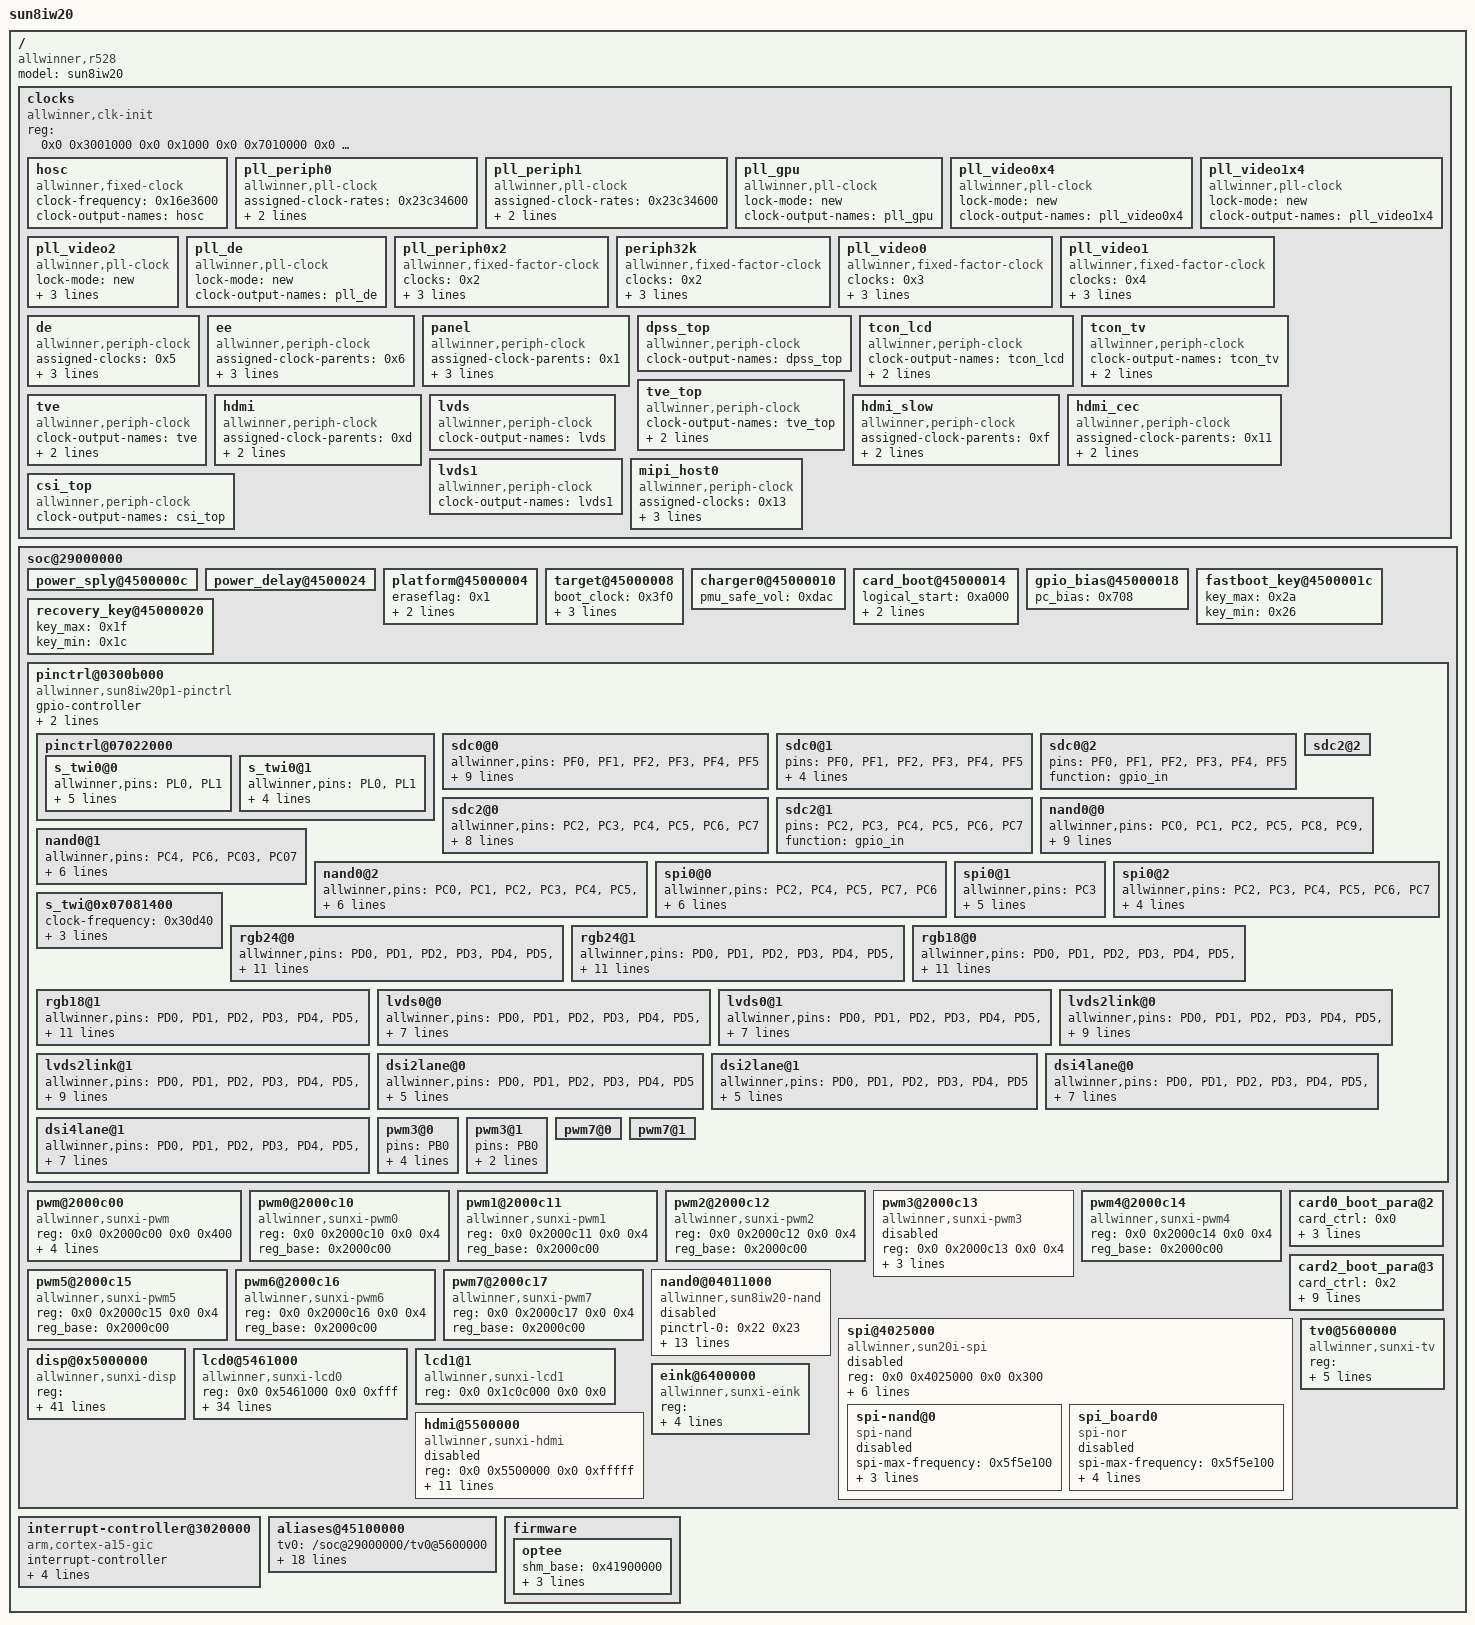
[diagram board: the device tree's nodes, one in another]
/dts-v1/;

/ {
	model = "sun8iw20";
	compatible = "allwinner,r528", "arm,sun8iw20p1";
	#address-cells = <0x2>;
	#size-cells = <0x2>;

	clocks {
		compatible = "allwinner,clk-init";
		device_type = "clocks";
		#address-cells = <0x2>;
		#size-cells = <0x2>;
		ranges;
		reg = <0x0 0x3001000 0x0 0x1000 0x0 0x7010000 0x0 0x400 0x0 0x7000000 0x0 0x4>;

		hosc {
			#clock-cells = <0x0>;
			compatible = "allwinner,fixed-clock";
			clock-frequency = <0x16e3600>;
			clock-output-names = "hosc";
			phandle = <0xf>;
		};

		pll_periph0 {
			#clock-cells = <0x0>;
			compatible = "allwinner,pll-clock";
			assigned-clock-rates = <0x23c34600>;
			lock-mode = "new";
			clock-output-names = "pll_periph0";
			phandle = <0x2>;
		};

		pll_periph1 {
			#clock-cells = <0x0>;
			compatible = "allwinner,pll-clock";
			assigned-clock-rates = <0x23c34600>;
			lock-mode = "new";
			clock-output-names = "pll_periph1";
		};

		pll_gpu {
			#clock-cells = <0x0>;
			compatible = "allwinner,pll-clock";
			lock-mode = "new";
			clock-output-names = "pll_gpu";
		};

		pll_video0x4 {
			#clock-cells = <0x0>;
			compatible = "allwinner,pll-clock";
			lock-mode = "new";
			clock-output-names = "pll_video0x4";
			phandle = <0x3>;
		};

		pll_video1x4 {
			#clock-cells = <0x0>;
			compatible = "allwinner,pll-clock";
			lock-mode = "new";
			clock-output-names = "pll_video1x4";
			phandle = <0x4>;
		};

		pll_video2 {
			#clock-cells = <0x0>;
			compatible = "allwinner,pll-clock";
			lock-mode = "new";
			assigned-clocks = <0x1>;
			assigned-clock-rates = <0x1406f400>;
			clock-output-names = "pll_video2";
			phandle = <0x1>;
		};

		pll_de {
			#clock-cells = <0x0>;
			compatible = "allwinner,pll-clock";
			lock-mode = "new";
			clock-output-names = "pll_de";
		};

		pll_periph0x2 {
			#clock-cells = <0x0>;
			compatible = "allwinner,fixed-factor-clock";
			clocks = <0x2>;
			clock-mult = <0x2>;
			clock-div = <0x1>;
			clock-output-names = "pll_periph0x2";
			phandle = <0x6>;
		};

		periph32k {
			#clock-cells = <0x0>;
			compatible = "allwinner,fixed-factor-clock";
			clocks = <0x2>;
			clock-mult = <0x2>;
			clock-div = <0x8f0d>;
			clock-output-names = "periph32k";
			phandle = <0x11>;
		};

		pll_video0 {
			#clock-cells = <0x0>;
			compatible = "allwinner,fixed-factor-clock";
			clocks = <0x3>;
			clock-mult = <0x1>;
			clock-div = <0x4>;
			clock-output-names = "pll_video0";
			phandle = <0xd>;
		};

		pll_video1 {
			#clock-cells = <0x0>;
			compatible = "allwinner,fixed-factor-clock";
			clocks = <0x4>;
			clock-mult = <0x1>;
			clock-div = <0x4>;
			clock-output-names = "pll_video1";
		};

		de {
			#clock-cells = <0x0>;
			compatible = "allwinner,periph-clock";
			assigned-clocks = <0x5>;
			assigned-clock-parents = <0x6>;
			assigned-clock-rates = <0x11e1a300>;
			clock-output-names = "de";
			phandle = <0x5>;
		};

		ee {
			#clock-cells = <0x0>;
			compatible = "allwinner,periph-clock";
			assigned-clock-parents = <0x6>;
			assigned-clock-rates = <0x11e1a300>;
			assigned-clocks = <0x7>;
			clock-output-names = "ee";
			phandle = <0x7>;
		};

		panel {
			#clock-cells = <0x0>;
			compatible = "allwinner,periph-clock";
			assigned-clock-parents = <0x1>;
			assigned-clock-rates = <0x1c9c380>;
			assigned-clocks = <0x8>;
			clock-output-names = "panel";
			phandle = <0x8>;
		};

		dpss_top {
			#clock-cells = <0x0>;
			compatible = "allwinner,periph-clock";
			clock-output-names = "dpss_top";
			phandle = <0x29>;
		};

		tcon_lcd {
			#clock-cells = <0x0>;
			compatible = "allwinner,periph-clock";
			clock-output-names = "tcon_lcd";
			assigned-clocks = <0x9>;
			assigned-clock-parents = <0x3>;
			phandle = <0x9>;
		};

		tcon_tv {
			#clock-cells = <0x0>;
			compatible = "allwinner,periph-clock";
			clock-output-names = "tcon_tv";
			assigned-clocks = <0xa>;
			assigned-clock-parents = <0x4>;
			phandle = <0xa>;
		};

		tve_top {
			#clock-cells = <0x0>;
			compatible = "allwinner,periph-clock";
			clock-output-names = "tve_top";
			assigned-clock-parents = <0x4>;
			assigned-clocks = <0xb>;
			phandle = <0xb>;
		};

		tve {
			#clock-cells = <0x0>;
			compatible = "allwinner,periph-clock";
			clock-output-names = "tve";
			assigned-clock-parents = <0x4>;
			assigned-clocks = <0xc>;
			phandle = <0xc>;
		};

		hdmi {
			#clock-cells = <0x0>;
			compatible = "allwinner,periph-clock";
			assigned-clock-parents = <0xd>;
			assigned-clocks = <0xe>;
			clock-output-names = "hdmi";
			phandle = <0xe>;
		};

		hdmi_slow {
			#clock-cells = <0x0>;
			compatible = "allwinner,periph-clock";
			assigned-clock-parents = <0xf>;
			assigned-clocks = <0x10>;
			clock-output-names = "hdmi_slow";
			phandle = <0x10>;
		};

		hdmi_cec {
			#clock-cells = <0x0>;
			compatible = "allwinner,periph-clock";
			assigned-clock-parents = <0x11>;
			assigned-clocks = <0x12>;
			clock-output-names = "hdmi_cec";
			phandle = <0x12>;
		};

		lvds {
			#clock-cells = <0x0>;
			compatible = "allwinner,periph-clock";
			clock-output-names = "lvds";
			phandle = <0x2a>;
		};

		lvds1 {
			#clock-cells = <0x0>;
			compatible = "allwinner,periph-clock";
			clock-output-names = "lvds1";
		};

		mipi_host0 {
			#clock-cells = <0x0>;
			compatible = "allwinner,periph-clock";
			assigned-clocks = <0x13>;
			assigned-clock-parents = <0x2>;
			assigned-clock-rates = <0x8f0d180>;
			clock-output-names = "mipi_host0";
			phandle = <0x13>;
		};

		csi_top {
			#clock-cells = <0x0>;
			compatible = "allwinner,periph-clock";
			clock-output-names = "csi_top";
		};
	};

	soc@29000000 {
		#address-cells = <0x2>;
		#size-cells = <0x2>;

		power_sply@4500000c {
			device_type = "power_sply";
		};

		power_delay@4500024 {
			device_type = "power_delay";
		};

		platform@45000004 {
			device_type = "platform";
			eraseflag = <0x1>;
			next_work = <0x3>;
			debug_mode = <0x1>;
		};

		target@45000008 {
			device_type = "target";
			boot_clock = <0x3f0>;
			storage_type = <0xffffffff>;
			burn_key = <0x1>;
			dragonboard_test = <0x0>;
		};

		charger0@45000010 {
			device_type = "charger0";
			pmu_safe_vol = <0xdac>;
		};

		card_boot@45000014 {
			device_type = "card_boot";
			logical_start = <0xa000>;
			sprite_gpio0 = <0x14 0x7 0x6 0x1 0xffffffff 0xffffffff 0x1>;
		};

		gpio_bias@45000018 {
			device_type = "gpio_bias";
			pc_bias = <0x708>;
		};

		fastboot_key@4500001c {
			device_type = "fastboot_key";
			key_max = <0x2a>;
			key_min = <0x26>;
		};

		recovery_key@45000020 {
			device_type = "recovery_key";
			key_max = <0x1f>;
			key_min = <0x1c>;
		};

		pinctrl@0300b000 {
			compatible = "allwinner,sun8iw20p1-pinctrl";
			device_type = "pio";
			gpio-controller;
			#size-cells = <0x0>;
			#gpio-cells = <0x6>;
			input-debounce = <0x0 0x0 0x0 0x0 0x0 0x0 0x0 0x0 0x0>;
			phandle = <0x14>;

			pinctrl@07022000 {

				s_twi0@0 {
					allwinner,pins = "PL0", "PL1";
					allwinner,pname = "s_twi0_scl", "s_twi0_sda";
					allwinner,function = "s_twi0";
					allwinner,muxsel = <0x2>;
					allwinner,drive = <0x1>;
					allwinner,pull = <0x1>;
					phandle = <0x15>;
				};

				s_twi0@1 {
					allwinner,pins = "PL0", "PL1";
					allwinner,function = "io_disabled";
					allwinner,muxsel = <0x7>;
					allwinner,drive = <0x1>;
					allwinner,pull = <0x0>;
				};
			};

			sdc0@0 {
				allwinner,pins = "PF0", "PF1", "PF2", "PF3", "PF4", "PF5";
				allwinner,function = "sdc0";
				allwinner,muxsel = <0x2>;
				allwinner,drive = <0x3>;
				allwinner,pull = <0x1>;
				pins = "PF0", "PF1", "PF2", "PF3", "PF4", "PF5";
				function = "sdc0";
				drive-strength = <0x1e>;
				bias-pull-up;
				power-source = <0xce4>;
				phandle = <0x20>;
			};

			sdc0@1 {
				pins = "PF0", "PF1", "PF2", "PF3", "PF4", "PF5";
				function = "sdc0";
				drive-strength = <0x1e>;
				bias-pull-up;
				power-source = <0x708>;
			};

			sdc0@2 {
				pins = "PF0", "PF1", "PF2", "PF3", "PF4", "PF5";
				function = "gpio_in";
			};

			sdc2@0 {
				allwinner,pins = "PC2", "PC3", "PC4", "PC5", "PC6", "PC7";
				allwinner,function = "sdc2";
				allwinner,muxsel = <0x3>;
				allwinner,drive = <0x3>;
				allwinner,pull = <0x1>;
				pins = "PC2", "PC3", "PC4", "PC5", "PC6", "PC7";
				function = "sdc2";
				drive-strength = <0x1e>;
				bias-pull-up;
				phandle = <0x21>;
			};

			sdc2@1 {
				pins = "PC2", "PC3", "PC4", "PC5", "PC6", "PC7";
				function = "gpio_in";
			};

			sdc2@2 {
			};

			nand0@0 {
				allwinner,pins = "PC0", "PC1", "PC2", "PC5", "PC8", "PC9", "PC10", "PC11", "PC12", "PC13", "PC14", "PC15", "PC16";
				allwinner,pname = "nand0_we", "nand0_ale", "nand0_cle", "nand0_nre", "nand0_d0", "nand0_d1", "nand0_d2", "nand0_d3", "nand0_d4", "nand0_d5", "nand0_d6", "nand0_d7", "nand0_ndqs";
				allwinner,function = "nand0";
				allwinner,muxsel = <0x2>;
				allwinner,drive = <0x1>;
				allwinner,pull = <0x0>;
				phandle = <0x22>;
			};

			nand0@1 {
				allwinner,pins = "PC4", "PC6", "PC03", "PC07";
				allwinner,pname = "nand0_ce0", "nand0_rb0", "nand0_ce1", "nand0_rb1";
				allwinner,function = "nand0";
				allwinner,muxsel = <0x2>;
				allwinner,drive = <0x1>;
				allwinner,pull = <0x1>;
				phandle = <0x23>;
			};

			nand0@2 {
				allwinner,pins = "PC0", "PC1", "PC2", "PC3", "PC4", "PC5", "PC6", "PC7", "PC8", "PC9", "PC10", "PC11", "PC12", "PC13", "PC14", "PC15", "PC16";
				allwinner,function = "io_disabled";
				allwinner,muxsel = <0x7>;
				allwinner,drive = <0x1>;
				allwinner,pull = <0x0>;
				phandle = <0x24>;
			};

			spi0@0 {
				allwinner,pins = "PC2", "PC4", "PC5", "PC7", "PC6";
				allwinner,pname = "spi0_sclk", "spi0_mosi", "spi0_miso", "spi0_hold", "spi0_wp";
				allwinner,function = "spi0";
				allwinner,muxsel = <0x2>;
				allwinner,drive = <0x1>;
				allwinner,pull = <0x0>;
				phandle = <0x25>;
			};

			spi0@1 {
				allwinner,pins = "PC3";
				allwinner,pname = "spi0_cs0";
				allwinner,function = "spi0";
				allwinner,muxsel = <0x2>;
				allwinner,drive = <0x1>;
				allwinner,pull = <0x1>;
				phandle = <0x26>;
			};

			spi0@2 {
				allwinner,pins = "PC2", "PC3", "PC4", "PC5", "PC6", "PC7";
				allwinner,function = "gpio_in";
				allwinner,muxsel = <0x0>;
				allwinner,drive = <0x1>;
				allwinner,pull = <0x0>;
				phandle = <0x27>;
			};

			s_twi@0x07081400 {
				clock-frequency = <0x30d40>;
				pinctrl-0 = <0x15>;
				no_suspend = <0x1>;
				twi_drv_used = <0x1>;
				status = "okay";
			};

			rgb24@0 {
				allwinner,pins = "PD0", "PD1", "PD2", "PD3", "PD4", "PD5", "PD6", "PD7", "PD8", "PD9", "PD10", "PD11", "PD12", "PD13", "PD14", "PD15", "PD16", "PD17", "PD18", "PD19", "PD20", "PD21", "PB2", "PB3", "PB4", "PB5", "PB6", "PB7";
				allwinner,pname = "PD0", "PD1", "PD2", "PD3", "PD4", "PD5", "PD6", "PD7", "PD8", "PD9", "PD10", "PD11", "PD12", "PD13", "PD14", "PD15", "PD16", "PD17", "PD18", "PD19", "PD20", "PD21", "PB2", "PB3", "PB4", "PB5", "PB6", "PB7";
				allwinner,function = "rgb18";
				allwinner,muxsel = <0x2>;
				allwinner,drive = <0x3>;
				allwinner,pull = <0x0>;
			};

			rgb24@1 {
				allwinner,pins = "PD0", "PD1", "PD2", "PD3", "PD4", "PD5", "PD6", "PD7", "PD8", "PD9", "PD10", "PD11", "PD12", "PD13", "PD14", "PD15", "PD16", "PD17", "PD18", "PD19", "PD20", "PD21", "PB2", "PB3", "PB4", "PB5", "PB6", "PB7";
				allwinner,pname = "PD0", "PD1", "PD2", "PD3", "PD4", "PD5", "PD6", "PD7", "PD8", "PD9", "PD10", "PD11", "PD12", "PD13", "PD14", "PD15", "PD16", "PD17", "PD18", "PD19", "PD20", "PD21", "PB2", "PB3", "PB4", "PB5", "PB6", "PB7";
				allwinner,function = "rgb18_suspend";
				allwinner,muxsel = <0xf>;
				allwinner,drive = <0x1>;
				allwinner,pull = <0x0>;
			};

			rgb18@0 {
				allwinner,pins = "PD0", "PD1", "PD2", "PD3", "PD4", "PD5", "PD6", "PD7", "PD8", "PD9", "PD10", "PD11", "PD12", "PD13", "PD14", "PD15", "PD16", "PD17", "PD18", "PD19", "PD20", "PD21";
				allwinner,pname = "PD0", "PD1", "PD2", "PD3", "PD4", "PD5", "PD6", "PD7", "PD8", "PD9", "PD10", "PD11", "PD12", "PD13", "PD14", "PD15", "PD16", "PD17", "PD18", "PD19", "PD20", "PD21";
				allwinner,function = "rgb18";
				allwinner,muxsel = <0x2>;
				allwinner,drive = <0x3>;
				allwinner,pull = <0x0>;
			};

			rgb18@1 {
				allwinner,pins = "PD0", "PD1", "PD2", "PD3", "PD4", "PD5", "PD6", "PD7", "PD8", "PD9", "PD10", "PD11", "PD12", "PD13", "PD14", "PD15", "PD16", "PD17", "PD18", "PD19", "PD20", "PD21";
				allwinner,pname = "PD0", "PD1", "PD2", "PD3", "PD4", "PD5", "PD6", "PD7", "PD8", "PD9", "PD10", "PD11", "PD12", "PD13", "PD14", "PD15", "PD16", "PD17", "PD18", "PD19", "PD20", "PD21";
				allwinner,function = "rgb18_suspend";
				allwinner,muxsel = <0x7>;
				allwinner,drive = <0x1>;
				allwinner,pull = <0x0>;
			};

			lvds0@0 {
				allwinner,pins = "PD0", "PD1", "PD2", "PD3", "PD4", "PD5", "PD6", "PD7", "PD8", "PD9";
				allwinner,pname = "PD0", "PD1", "PD2", "PD3", "PD4", "PD5", "PD6", "PD7", "PD8", "PD9";
				allwinner,function = "lvds0";
				allwinner,muxsel = <0x3>;
				allwinner,drive = <0x3>;
				allwinner,pull = <0x0>;
				phandle = <0x2b>;
			};

			lvds0@1 {
				allwinner,pins = "PD0", "PD1", "PD2", "PD3", "PD4", "PD5", "PD6", "PD7", "PD8", "PD9";
				allwinner,pname = "PD0", "PD1", "PD2", "PD3", "PD4", "PD5", "PD6", "PD7", "PD8", "PD9";
				allwinner,function = "io_disabled";
				allwinner,muxsel = <0x7>;
				allwinner,drive = <0x3>;
				allwinner,pull = <0x0>;
				phandle = <0x2c>;
			};

			lvds2link@0 {
				allwinner,pins = "PD0", "PD1", "PD2", "PD3", "PD4", "PD5", "PD6", "PD7", "PD8", "PD9", "PD10", "PD11", "PD12", "PD13", "PD14", "PD15", "PD16", "PD17", "PD18", "PD19";
				allwinner,pname = "PD0", "PD1", "PD2", "PD3", "PD4", "PD5", "PD6", "PD7", "PD8", "PD9", "PD10", "PD11", "PD12", "PD13", "PD14", "PD15", "PD16", "PD17", "PD18", "PD19";
				allwinner,function = "lvds0";
				allwinner,muxsel = <0x3>;
				allwinner,drive = <0x3>;
				allwinner,pull = <0x0>;
			};

			lvds2link@1 {
				allwinner,pins = "PD0", "PD1", "PD2", "PD3", "PD4", "PD5", "PD6", "PD7", "PD8", "PD9", "PD10", "PD11", "PD12", "PD13", "PD14", "PD15", "PD16", "PD17", "PD18", "PD19";
				allwinner,pname = "PD0", "PD1", "PD2", "PD3", "PD4", "PD5", "PD6", "PD7", "PD8", "PD9", "PD10", "PD11", "PD12", "PD13", "PD14", "PD15", "PD16", "PD17", "PD18", "PD19";
				allwinner,function = "lvds0_suspend";
				allwinner,muxsel = <0xf>;
				allwinner,drive = <0x3>;
				allwinner,pull = <0x0>;
			};

			dsi2lane@0 {
				allwinner,pins = "PD0", "PD1", "PD2", "PD3", "PD4", "PD5";
				allwinner,pname = "PD0", "PD1", "PD2", "PD3", "PD4", "PD5";
				allwinner,function = "dsi2lane";
				allwinner,muxsel = <0x4>;
				allwinner,drive = <0x3>;
				allwinner,pull = <0x0>;
			};

			dsi2lane@1 {
				allwinner,pins = "PD0", "PD1", "PD2", "PD3", "PD4", "PD5";
				allwinner,pname = "PD0", "PD1", "PD2", "PD3", "PD4", "PD5";
				allwinner,function = "dsi2lane_suspend";
				allwinner,muxsel = <0xf>;
				allwinner,drive = <0x1>;
				allwinner,pull = <0x0>;
			};

			dsi4lane@0 {
				allwinner,pins = "PD0", "PD1", "PD2", "PD3", "PD4", "PD5", "PD6", "PD7", "PD8", "PD9";
				allwinner,pname = "PD0", "PD1", "PD2", "PD3", "PD4", "PD5", "PD6", "PD7", "PD8", "PD9";
				allwinner,function = "dsi4lane";
				allwinner,muxsel = <0x4>;
				allwinner,drive = <0x3>;
				allwinner,pull = <0x0>;
			};

			dsi4lane@1 {
				allwinner,pins = "PD0", "PD1", "PD2", "PD3", "PD4", "PD5", "PD6", "PD7", "PD8", "PD9";
				allwinner,pname = "PD0", "PD1", "PD2", "PD3", "PD4", "PD5", "PD6", "PD7", "PD8", "PD9";
				allwinner,function = "dsi4lane_suspend";
				allwinner,muxsel = <0x7>;
				allwinner,drive = <0x1>;
				allwinner,pull = <0x0>;
			};

			pwm3@0 {
				pins = "PB0";
				function = "pwm3";
				muxsel = <0x2>;
				drive-strength = <0xa>;
				bias-pull-up;
				phandle = <0x1e>;
			};

			pwm3@1 {
				pins = "PB0";
				muxsel = <0x0>;
				function = "gpio_in";
				phandle = <0x1f>;
			};

			pwm7@0 {
			};

			pwm7@1 {
			};
		};

		pwm@2000c00 {
			#pwm-cells = <0x3>;
			compatible = "allwinner,sunxi-pwm";
			reg = <0x0 0x2000c00 0x0 0x400>;
			pwm-number = <0x8>;
			pwm-base = <0x0>;
			sunxi-pwms = <0x16 0x17 0x18 0x19 0x1a 0x1b 0x1c 0x1d>;
		};

		pwm0@2000c10 {
			compatible = "allwinner,sunxi-pwm0";
			pinctrl-names = "active", "sleep";
			reg = <0x0 0x2000c10 0x0 0x4>;
			reg_base = <0x2000c00>;
			phandle = <0x16>;
		};

		pwm1@2000c11 {
			compatible = "allwinner,sunxi-pwm1";
			pinctrl-names = "active", "sleep";
			reg = <0x0 0x2000c11 0x0 0x4>;
			reg_base = <0x2000c00>;
			phandle = <0x17>;
		};

		pwm2@2000c12 {
			compatible = "allwinner,sunxi-pwm2";
			pinctrl-names = "active", "sleep";
			reg = <0x0 0x2000c12 0x0 0x4>;
			reg_base = <0x2000c00>;
			phandle = <0x18>;
		};

		pwm3@2000c13 {
			compatible = "allwinner,sunxi-pwm3";
			pinctrl-names = "active", "sleep";
			reg = <0x0 0x2000c13 0x0 0x4>;
			reg_base = <0x2000c00>;
			pinctrl-0 = <0x1e>;
			pinctrl-1 = <0x1f>;
			status = "disabled";
			phandle = <0x19>;
		};

		pwm4@2000c14 {
			compatible = "allwinner,sunxi-pwm4";
			pinctrl-names = "active", "sleep";
			reg = <0x0 0x2000c14 0x0 0x4>;
			reg_base = <0x2000c00>;
			phandle = <0x1a>;
		};

		pwm5@2000c15 {
			compatible = "allwinner,sunxi-pwm5";
			pinctrl-names = "active", "sleep";
			reg = <0x0 0x2000c15 0x0 0x4>;
			reg_base = <0x2000c00>;
			phandle = <0x1b>;
		};

		pwm6@2000c16 {
			compatible = "allwinner,sunxi-pwm6";
			pinctrl-names = "active", "sleep";
			reg = <0x0 0x2000c16 0x0 0x4>;
			reg_base = <0x2000c00>;
			phandle = <0x1c>;
		};

		pwm7@2000c17 {
			compatible = "allwinner,sunxi-pwm7";
			pinctrl-names = "active", "sleep";
			reg = <0x0 0x2000c17 0x0 0x4>;
			reg_base = <0x2000c00>;
			phandle = <0x1d>;
		};

		card0_boot_para@2 {
			device_type = "card0_boot_para";
			card_ctrl = <0x0>;
			card_high_speed = <0x1>;
			card_line = <0x4>;
			pinctrl-0 = <0x20>;
		};

		card2_boot_para@3 {
			device_type = "card2_boot_para";
			card_ctrl = <0x2>;
			card_high_speed = <0x1>;
			card_line = <0x4>;
			pinctrl-0 = <0x21>;
			sdc_ex_dly_used = <0x2>;
			sdc_io_1v8 = <0x1>;
			sdc_tm4_win_th = <0x8>;
			sdc_tm4_hs200_max_freq = <0x96>;
			sdc_tm4_hs400_max_freq = <0x64>;
			sdc_type = "tm4";
		};

		nand0@04011000 {
			device_type = "nand0";
			compatible = "allwinner,sun8iw20-nand";
			pinctrl-names = "default", "sleep";
			pinctrl-0 = <0x22 0x23>;
			pinctrl-1 = <0x24>;
			nand0_regulator1 = "vcc-nand";
			nand0_regulator2 = "none";
			nand0_cache_level = <0x55aaaa55>;
			nand0_flush_cache_num = <0x55aaaa55>;
			nand0_capacity_level = <0x55aaaa55>;
			nand0_id_number_ctl = <0x55aaaa55>;
			nand0_print_level = <0x55aaaa55>;
			nand0_p0 = <0x55aaaa55>;
			nand0_p1 = <0x55aaaa55>;
			nand0_p2 = <0x55aaaa55>;
			nand0_p3 = <0x55aaaa55>;
			chip_code = "sun8iw20";
			status = "disabled";
		};

		spi@4025000 {
			#address-cells = <0x1>;
			#size-cells = <0x0>;
			compatible = "allwinner,sun20i-spi";
			device_type = "spi0";
			reg = <0x0 0x4025000 0x0 0x300>;
			clock-frequency = <0x5f5e100>;
			pinctrl-0 = <0x25 0x26>;
			pinctrl-1 = <0x27>;
			pinctrl-names = "default", "sleep";
			spi_slave_mode = <0x0>;
			spi0_cs_number = <0x1>;
			spi0_cs_bitmap = <0x1>;
			status = "disabled";

			spi-nand@0 {
				compatible = "spi-nand";
				spi-max-frequency = <0x5f5e100>;
				reg = <0x0>;
				spi-rx-bus-width = <0x1>;
				spi-tx-bus-width = <0x1>;
				status = "disabled";
			};

			spi_board0 {
				device_type = "spi_board0";
				compatible = "spi-nor";
				spi-max-frequency = <0x5f5e100>;
				m25p,fast-read = <0x1>;
				reg = <0x0>;
				spi-rx-bus-width = <0x4>;
				spi-tx-bus-width = <0x4>;
				status = "disabled";
			};
		};

		disp@0x5000000 {
			compatible = "allwinner,sunxi-disp";
			reg = <0x0 0x5000000 0x0 0x3fffff 0x0 0x5460000 0x0 0xfff 0x0 0x5461000 0x0 0xfff 0x0 0x5470000 0x0 0xfff 0x0 0x5450000 0x0 0x1fff>;
			interrupts = <0x0 0x5a 0x4 0x0 0x5b 0x4 0x0 0x5c 0x4>;
			interrupt-parent = <0x28>;
			clocks = <0x5 0x29 0x9 0xa 0x2a 0x13>;
			boot_disp = <0x0>;
			boot_disp1 = <0x0>;
			boot_disp2 = <0x0>;
			fb_base = <0x0>;
			status = "okay";
			disp_init_enable = <0x1>;
			disp_mode = <0x0>;
			screen0_output_type = <0x1>;
			screen0_output_mode = <0x4>;
			screen1_output_type = <0x1>;
			screen1_output_mode = <0x4>;
			screen1_output_format = <0x0>;
			screen1_output_bits = <0x0>;
			screen1_output_eotf = <0x4>;
			screen1_output_cs = <0x101>;
			screen1_output_dvi_hdmi = <0x2>;
			screen1_output_range = <0x2>;
			screen1_output_scan = <0x0>;
			screen1_output_aspect_ratio = <0x8>;
			dev0_output_type = <0x1>;
			dev0_output_mode = <0x4>;
			dev0_screen_id = <0x0>;
			dev0_do_hpd = <0x0>;
			dev1_output_type = <0x1>;
			dev1_output_mode = <0x4>;
			dev1_screen_id = <0x1>;
			dev1_do_hpd = <0x0>;
			def_output_dev = <0x0>;
			hdmi_mode_check = <0x1>;
			fb0_format = <0x0>;
			fb0_width = <0x400>;
			fb0_height = <0x258>;
			fb1_format = <0x0>;
			fb1_width = <0x400>;
			fb1_height = <0x258>;
			chn_cfg_mode = <0x1>;
			disp_para_zone = <0x1>;
		};

		tv0@5600000 {
			compatible = "allwinner,sunxi-tv";
			reg = <0x0 0x5600000 0x0 0x3fff 0x0 0x5604000 0x0 0x3fff>;
			clocks = <0xb 0xc>;
			device_type = "tv0";
			pinctrl-names = "active", "sleep";
			status = "okay";
			interface = <0x1>;
			dac_type0 = <0x0>;
			dac_src0 = <0x0>;
		};

		lcd0@5461000 {
			#address-cells = <0x2>;
			#size-cells = <0x2>;
			compatible = "allwinner,sunxi-lcd0";
			reg = <0x0 0x5461000 0x0 0xfff>;
			pinctrl-names = "active", "sleep";
			status = "okay";
			lcd_used = <0x1>;
			lcd_driver_name = "default_lcd";
			lcd_backlight = <0x64>;
			lcd_if = <0x3>;
			lcd_x = <0x400>;
			lcd_y = <0x258>;
			lcd_width = <0x9a>;
			lcd_height = <0x56>;
			lcd_dclk_freq = <0x31>;
			lcd_pwm_used = <0x1>;
			lcd_pwm_ch = <0x2>;
			lcd_pwm_freq = <0xc350>;
			lcd_pwm_pol = <0x1>;
			lcd_pwm_max_limit = <0xff>;
			lcd_hbp = <0xa0>;
			lcd_ht = <0x52c>;
			lcd_hspw = <0x74>;
			lcd_vbp = <0x18>;
			lcd_vt = <0x275>;
			lcd_vspw = <0x3>;
			lcd_lvds_if = <0x0>;
			lcd_lvds_colordepth = <0x0>;
			lcd_lvds_mode = <0x0>;
			lcd_frm = <0x0>;
			lcd_hv_clk_phase = <0x0>;
			lcd_hv_sync_polarity = <0x0>;
			lcd_gamma_en = <0x0>;
			lcd_bright_curve_en = <0x0>;
			lcd_cmap_en = <0x0>;
			deu_mode = <0x0>;
			lcdgamma4iep = <0x16>;
			smart_color = <0x5a>;
			pinctrl-0 = <0x2b>;
			pinctrl-1 = <0x2c>;
		};

		lcd1@1 {
			compatible = "allwinner,sunxi-lcd1";
			reg = <0x0 0x1c0c000 0x0 0x0>;
			pinctrl-names = "active", "sleep";
			status = "okay";
		};

		hdmi@5500000 {
			compatible = "allwinner,sunxi-hdmi";
			reg = <0x0 0x5500000 0x0 0xfffff>;
			interrupts = <0x0 0x5d 0x4>;
			interrupt-parent = <0x28>;
			clocks = <0x10 0x12 0xa>;
			status = "disabled";
			hdmi_used = <0x0>;
			hdmi_power_cnt = <0x0>;
			hdmi_hdcp_enable = <0x1>;
			hdmi_hdcp22_enable = <0x0>;
			hdmi_cec_support = <0x1>;
			hdmi_cec_super_standby = <0x0>;
			ddc_en_io_ctrl = <0x0>;
			power_io_ctrl = <0x0>;
		};

		eink@6400000 {
			compatible = "allwinner,sunxi-eink";
			pinctrl-names = "active", "sleep";
			reg = <0x0 0x6400000 0x0 0x1ffff 0x0 0x6000000 0x0 0x3fffff>;
			interrupts = <0x0 0x5a 0x4 0x0 0x58 0x4>;
			clocks = <0x5 0x7 0x8>;
			interrupt-parent = <0x28>;
			status = "okay";
		};
	};

	interrupt-controller@3020000 {
		compatible = "arm,cortex-a15-gic", "arm,cortex-a9-gic";
		#interrupt-cells = <0x3>;
		#address-cells = <0x0>;
		device_type = "gic";
		interrupt-controller;
		reg = <0x0 0x3021000 0x0 0x1000 0x0 0x3022000 0x0 0x2000 0x0 0x3024000 0x0 0x2000 0x0 0x3026000 0x0 0x2000>;
		interrupts = <0x1 0x9 0xf04>;
		interrupt-parent = <0x28>;
		phandle = <0x28>;
	};

	aliases@45100000 {
		tv0 = "/soc@29000000/tv0@5600000";
		nand0 = "/soc@29000000/nand0@04011000";
		twi6 = "/soc@29000000/pinctrl@0300b000/s_twi@0x07081400";
		pwm = "/soc@29000000/pwm@2000c00";
		pwm0 = "/soc@29000000/pwm0@2000c10";
		pwm1 = "/soc@29000000/pwm1@2000c11";
		pwm2 = "/soc@29000000/pwm2@2000c12";
		pwm3 = "/soc@29000000/pwm3@2000c13";
		pwm4 = "/soc@29000000/pwm4@2000c14";
		pwm5 = "/soc@29000000/pwm5@2000c15";
		pwm6 = "/soc@29000000/pwm6@2000c16";
		pwm7 = "/soc@29000000/pwm7@2000c17";
		disp = "/soc@29000000/disp@0x5000000";
		hdmi = "/soc@29000000/hdmi@5500000";
		lcd0 = "/soc@29000000/lcd0@5461000";
		lcd1 = "/soc@29000000/lcd1@1";
		eink = "/soc@29000000/eink@6400000";
		spi0 = "/soc@29000000/spi@4025000";
	};

	firmware {

		optee {
			shm_base = <0x41900000>;
			shm_size = <0x200000>;
			ta_ram_base = <0x41c00000>;
			ta_ram_size = <0x400000>;
		};
	};
};
